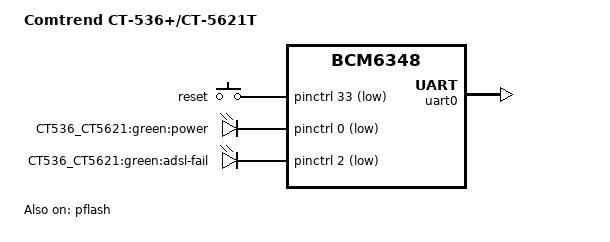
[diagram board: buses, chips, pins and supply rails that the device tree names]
/dts-v1/;

#include "bcm6348.dtsi"

#include <dt-bindings/input/input.h>

/ {
	model = "Comtrend CT-536+/CT-5621T";
	compatible = "comtrend,ct-536plus", "brcm,bcm6348";

	aliases {
		led-boot = &led_power_green;
		led-failsafe = &led_power_green;
		led-running = &led_power_green;
		led-upgrade = &led_power_green;
	};

	chosen {
		bootargs = "rootfstype=squashfs,jffs2 noinitrd console=ttyS0,115200";
		stdout-path = "serial0:115200n8";
	};

	keys {
		compatible = "gpio-keys-polled";
		#address-cells = <1>;
		#size-cells = <0>;
		poll-interval = <20>;

		reset {
			label = "reset";
			gpios = <&pinctrl 33 1>;
			linux,code = <KEY_RESTART>;
			debounce-interval = <60>;
		};
	};

	leds {
		compatible = "gpio-leds";

		led_power_green: power_green {
			label = "CT536_CT5621:green:power";
			gpios = <&pinctrl 0 1>;
			default-state = "on";
		};
		adsl_fail_green {
			label = "CT536_CT5621:green:adsl-fail";
			gpios = <&pinctrl 2 1>;
		};
	};
};

&pflash {
	status = "okay";

	partitions {
		compatible = "fixed-partitions";
		#address-cells = <1>;
		#size-cells = <1>;

		cfe@0 {
			label = "CFE";
			reg = <0x000000 0x010000>;
			read-only;
		};

		linux@10000 {
			label = "linux";
			reg = <0x010000 0x3e0000>;
			compatible = "brcm,bcm963xx-imagetag";
		};

		nvram@3f0000 {
			label = "nvram";
			reg = <0x3f0000 0x010000>;
		};
	};
};

&pinctrl {
	pinctrl-names = "default";
	pinctrl-0 = <&pinctrl_pci &pinctrl_ext_mii &pinctrl_mii_pccard>;
};

&uart0 {
	status = "okay";
};
